# MIMXRT1021 register map
Vendor: nxp.com; File version: 1.0
CPU: CM7 r0p1, little endian, MPU, FPU, VTOR, 4 interrupt priority bits
Registers are 32-bit, read-write, reset 0x0 unless marked. A register's access mark holds for its fields unless they carry their own. Offsets are from the block's base; [hi:lo] are bit positions; {n}, {i} and the like mark numbered series; 'fields as' and 'values as' point back to an identical list.

## LPSPI1 — LPSPI
Base 0x40394000
Same registers: LPSPI2 0x40398000, LPSPI3 0x4039C000, LPSPI4 0x403A0000
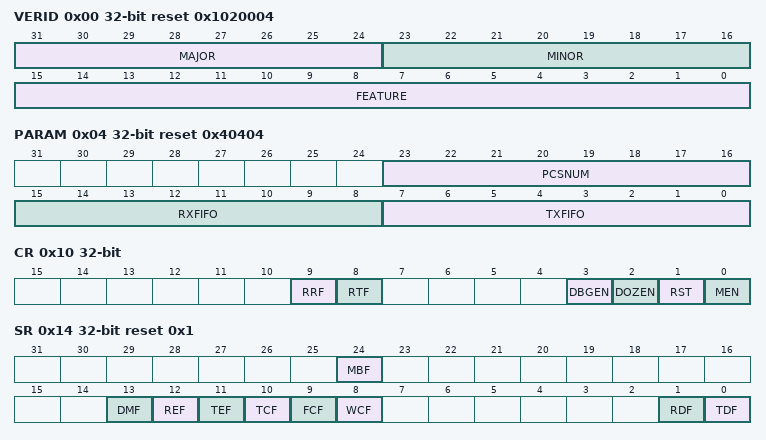
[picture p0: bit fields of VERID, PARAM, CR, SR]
0x00 VERID ro reset 0x1020004 — Version ID Register
  [31:24] MAJOR — Major Version Number
  [23:16] MINOR — Minor Version Number
  [15:0] FEATURE — Module Identification Number
    4=STANDARD (Standard feature set supporting a 32-bit shift register.)
0x04 PARAM ro reset 0x40404 — Parameter Register
  [23:16] PCSNUM — PCS Number
  [15:8] RXFIFO — Receive FIFO Size
  [7:0] TXFIFO — Transmit FIFO Size
0x10 CR — Control Register
  [9] RRF wo — Reset Receive FIFO
    0=NO_EFFECT; 1=RXFIFO_RST (Receive FIFO is reset)
  [8] RTF wo — Reset Transmit FIFO
    0=NO_EFFECT; 1=TXFIFO_RST (Transmit FIFO is reset)
  [3] DBGEN — Debug Enable
    0=DISABLED (LPSPI module is disabled in debug mode); 1=ENABLED (LPSPI module is enabled in debug mode)
  [2] DOZEN — Doze Mode Enable
    0=ENABLED (LPSPI module is enabled in Doze mode); 1=DISABLED (LPSPI module is disabled in Doze mode)
  [1] RST — Software Reset
    0=NOT_RESET (Module is not reset); 1=RESET (Module is reset)
  [0] MEN — Module Enable
    0=DISABLED (Module is disabled); 1=ENABLED (Module is enabled)
0x14 SR reset 0x1 — Status Register
  [24] MBF ro — Module Busy Flag
    0=IDLE (LPSPI is idle); 1=BUSY (LPSPI is busy)
  [13] DMF write-1-clears — Data Match Flag
    0=NO_MATCH (Have not received matching data); 1=MATCH (Have received matching data)
  [12] REF write-1-clears — Receive Error Flag
    0=NOT_OVERFLOWED (Receive FIFO has not overflowed); 1=OVERFLOWED (Receive FIFO has overflowed)
  [11] TEF write-1-clears — Transmit Error Flag
    0=NO_UNDERRUN (Transmit FIFO underrun has not occurred); 1=UNDERRUN (Transmit FIFO underrun has occurred)
  [10] TCF write-1-clears — Transfer Complete Flag
    0=NOT_COMPLETED (All transfers have not completed); 1=COMPLETED (All transfers have completed)
  [9] FCF write-1-clears — Frame Complete Flag
    0=NOT_COMPLETED (Frame transfer has not completed); 1=COMPLETED (Frame transfer has completed)
  [8] WCF write-1-clears — Word Complete Flag
    0=NOT_COMPLETED (Transfer of a received word has not yet completed); 1=COMPLETED (Transfer of a received word has completed)
  [1] RDF ro — Receive Data Flag
    0=NOTREADY (Receive Data is not ready); 1=READY (Receive data is ready)
  [0] TDF ro — Transmit Data Flag
    0=TXDATA_NOT_REQST (Transmit data not requested); 1=TXDATA_REQST (Transmit data is requested)
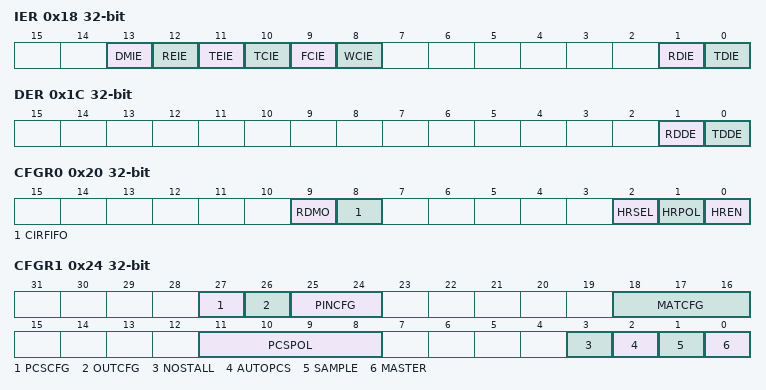
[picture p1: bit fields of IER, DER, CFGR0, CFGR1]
0x18 IER — Interrupt Enable Register
  [all] fields
    0=DISABLED; 1=ENABLED
  [13] DMIE — Data Match Interrupt Enable
  [12] REIE — Receive Error Interrupt Enable
  [11] TEIE — Transmit Error Interrupt Enable
  [10] TCIE — Transfer Complete Interrupt Enable
  [9] FCIE — Frame Complete Interrupt Enable
  [8] WCIE — Word Complete Interrupt Enable
  [1] RDIE — Receive Data Interrupt Enable
  [0] TDIE — Transmit Data Interrupt Enable
0x1C DER — DMA Enable Register
  [1] RDDE — Receive Data DMA Enable
    0=DISABLED (DMA request is disabled); 1=ENABLED (DMA request is enabled)
  [0] TDDE — Transmit Data DMA Enable
    values as RDDE
0x20 CFGR0 — Configuration Register 0
  [9] RDMO — Receive Data Match Only
    0=STORED (Received data is stored in the receive FIFO as in normal operations); 1=DISCARDED (Received data is discarded unless the Data Match Flag (DMF) is set)
  [8] CIRFIFO — Circular FIFO Enable
    0=DISABLED (Circular FIFO is disabled); 1=ENABLED (Circular FIFO is enabled)
  [2] HRSEL — Host Request Select
    0=HREQPIN (Host request input is the LPSPI_HREQ pin); 1=INPUT_TRIGGER (Host request input is the input trigger)
  [1] HRPOL — Host Request Polarity
    0=DISABLED (LPSPI_HREQ pin is active high provided PCSPOL[1] is clear); 1=ENABLED (LPSPI_HREQ pin is active low provided PCSPOL[1] is clear)
  [0] HREN — Host Request Enable
    0=DISABLED (Host request is disabled); 1=ENABLED (Host request is enabled)
0x24 CFGR1 — Configuration Register 1
  [27] PCSCFG — Peripheral Chip Select Configuration
    0=CHIP_SELECT (PCS[3:2] are configured for chip select function); 1=HALFDUPLEX4BIT (PCS[3:2] are configured for half-duplex 4-bit transfers (PCS[3:2] = DATA[3:2]))
  [26] OUTCFG — Output Configuration
    0=RETAIN_LASTVALUE (Output data retains last value when chip select is negated); 1=TRISTATED (Output data is tristated when chip select is negated)
  [25:24] PINCFG — Pin Configuration
    0=SIN_IN_SOUT_OUT (SIN is used for input data and SOUT is used for output data); 1=SIN_BOTH_IN_OUT (SIN is used for both input and output data, only half-duplex serial transfers are supported); 2=SOUT_BOTH_IN_OUT (SOUT is used for both input and output data, only half-duplex serial transfers are supported); 3=SOUT_IN_SIN_OUT (SOUT is used for input data and SIN is used for output data)
  [18:16] MATCFG — Match Configuration
    0=DISABLED (Match is disabled); 2=ENABLED_FIRSTDATAMATCH (010b - Match is enabled, if 1st data word equals MATCH0 OR MATCH1, i.e., (1st data word = MATCH0 + MATCH1)); 3=ENABLED_ANYDATAMATCH (011b - Match is enabled, if any data word equals MATCH0 OR MATCH1, i.e., (any data word = MATCH0 + MATCH1)); 4=ENABLED_DATAMATCH_100 (100b - Match is enabled, if 1st data word equals MATCH0 AND 2nd data word equals MATCH1, i.e., [(1st data word = MATCH0) * (2nd data word = MATCH1)]); 5=ENABLED_DATAMATCH_101 (101b - Match is enabled, if any data word equals MATCH0 AND the next data word equals MATCH1, i.e., [(any data word = MATCH0) * (next data word = MATCH1)]); 6=ENABLED_DATAMATCH_110 (110b - Match is enabled, if (1st data word AND MATCH1) equals (MATCH0 AND MATCH1), i.e., [(1st data word * MATCH1) = (MATCH0 * MATCH1)]); 7=ENABLED_DATAMATCH_111 (111b - Match is enabled, if (any data word AND MATCH1) equals (MATCH0 AND MATCH1), i.e., [(any data word * MATCH1) = (MATCH0 * MATCH1)])
  [11:8] PCSPOL — Peripheral Chip Select Polarity
  [3] NOSTALL
    0=DISABLED (Transfers will stall when the transmit FIFO is empty); 1=ENABLED (Transfers will not stall, allowing transmit FIFO underruns to occur)
  [2] AUTOPCS — Automatic PCS
    0=DISABLED (Automatic PCS generation is disabled); 1=ENABLED (Automatic PCS generation is enabled)
  [1] SAMPLE — Sample Point
    0=ON_SCK_EDGE (Input data is sampled on SCK edge); 1=ON_DELAYED_SCK_EDGE (Input data is sampled on delayed SCK edge)
  [0] MASTER — Master Mode
    0=SLAVE_MODE; 1=MASTER_MODE
0x30 DMR0 — Data Match Register 0
  [31:0] MATCH0 — Match 0 Value
0x34 DMR1 — Data Match Register 1
  [31:0] MATCH1 — Match 1 Value
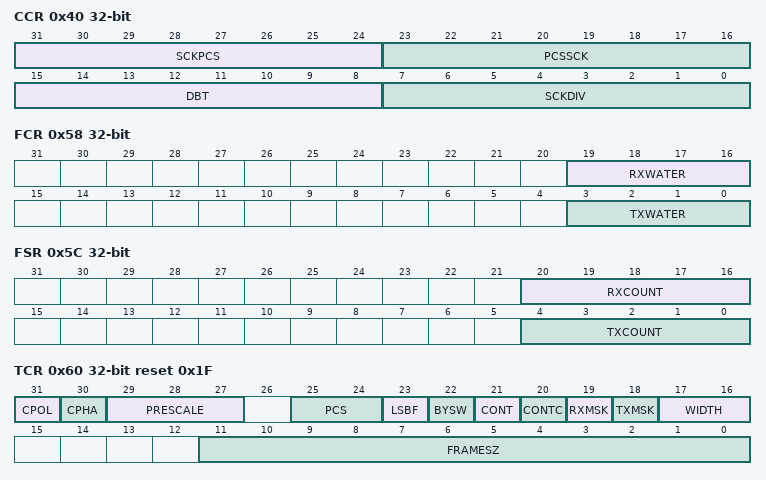
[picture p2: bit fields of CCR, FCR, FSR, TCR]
0x40 CCR — Clock Configuration Register
  [31:24] SCKPCS — SCK-to-PCS Delay
  [23:16] PCSSCK — PCS-to-SCK Delay
  [15:8] DBT — Delay Between Transfers
  [7:0] SCKDIV — SCK Divider
0x58 FCR — The FIFO Control register contains the RXWATER and TXWATER control fields.
  [19:16] RXWATER — Receive FIFO Watermark
  [3:0] TXWATER — Transmit FIFO Watermark
0x5C FSR ro — FIFO Status Register
  [20:16] RXCOUNT — Receive FIFO Count
  [4:0] TXCOUNT — Transmit FIFO Count
0x60 TCR reset 0x1F — Transmit Command Register
  [31] CPOL — Clock Polarity
    0=INACTIVE_LOW (The inactive state value of SCK is low); 1=INACTIVE_HIGH (The inactive state value of SCK is high)
  [30] CPHA — Clock Phase
    0=CAPTURED (Data is captured on the leading edge of SCK and changed on the following edge of SCK); 1=CHANGED (Data is changed on the leading edge of SCK and captured on the following edge of SCK)
  [29:27] PRESCALE — Prescaler Value
    0=DIVIDEBY1; 1=DIVIDEBY2; 2=DIVIDEBY4; 3=DIVIDEBY8; 4=DIVIDEBY16; 5=DIVIDEBY32; 6=DIVIDEBY64; 7=DIVIDEBY128
  [25:24] PCS — Peripheral Chip Select
    {v}=TX_PCS{v} (Transfer using LPSPI_PCS[{v}]) (v=0..3)
  [23] LSBF — LSB First
    0=MSB_FIRST (Data is transferred MSB first); 1=LSB_FIRST (Data is transferred LSB first)
  [22] BYSW — Byte Swap
    0=DISABLED (Byte swap is disabled); 1=ENABLED (Byte swap is enabled)
  [21] CONT — Continuous Transfer
    0=DISABLED (Continuous transfer is disabled); 1=ENABLED (Continuous transfer is enabled)
  [20] CONTC — Continuing Command
    0=START (Command word for start of new transfer); 1=CONTINUE (Command word for continuing transfer)
  [19] RXMSK — Receive Data Mask
    0=NORMAL (Normal transfer); 1=MASK (Receive data is masked)
  [18] TXMSK — Transmit Data Mask
    0=NORMAL (Normal transfer); 1=MASK (Mask transmit data)
  [17:16] WIDTH — Transfer Width
    0=ONEBIT (1 bit transfer); 1=TWOBIT (2 bit transfer); 2=FOURBIT (4 bit transfer)
  [11:0] FRAMESZ — Frame Size
0x64 TDR wo — Transmit Data Register
  [31:0] DATA — Transmit Data
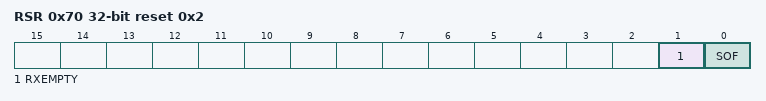
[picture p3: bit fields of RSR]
0x70 RSR ro reset 0x2 — Receive Status Register
  [1] RXEMPTY — RX FIFO Empty
    0=NOT_EMPTY (RX FIFO is not empty); 1=EMPTY (RX FIFO is empty)
  [0] SOF — Start Of Frame
    0=NEXT_DATAWORD (Subsequent data word received after LPSPI_PCS assertion); 1=FIRST_DATAWORD (First data word received after LPSPI_PCS assertion)
0x74 RDR ro — Receive Data Register
  [31:0] DATA — Receive Data
